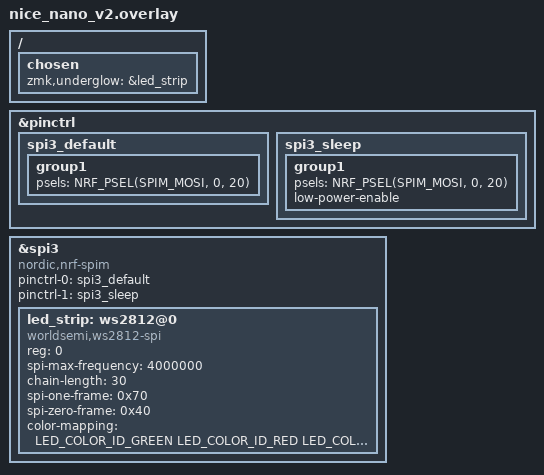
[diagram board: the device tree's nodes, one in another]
#include <dt-bindings/led/led.h>

/*
 * Official Keyball44 PCB (Yowkees) + QMK use WS2812_DI_PIN D3.
 * On nice!nano / ProMicro nRF52840 that is P0.20.
 * spi3 keeps the right-half trackball on spi1.
 *
 * Note: OLED I2C SCL is also on D3/P0.20 on this PCB. QMK bitbangs around
 * that; ZMK's SPI strip driver owns the pin. If OLED glitches after flashing,
 * that pin share is the reason — report back and we can tune.
 */
&pinctrl {
    spi3_default: spi3_default {
        group1 {
            psels = <NRF_PSEL(SPIM_MOSI, 0, 20)>;
        };
    };

    spi3_sleep: spi3_sleep {
        group1 {
            psels = <NRF_PSEL(SPIM_MOSI, 0, 20)>;
            low-power-enable;
        };
    };
};

&spi3 {
    compatible = "nordic,nrf-spim";
    status = "okay";

    pinctrl-0 = <&spi3_default>;
    pinctrl-1 = <&spi3_sleep>;
    pinctrl-names = "default", "sleep";

    led_strip: ws2812@0 {
        compatible = "worldsemi,ws2812-spi";
        reg = <0>;
        spi-max-frequency = <4000000>;

        /* Official Keyball44: RGBLED_SPLIT { 30, 30 } */
        chain-length = <30>;
        spi-one-frame = <0x70>;
        spi-zero-frame = <0x40>;

        color-mapping = <LED_COLOR_ID_GREEN
                         LED_COLOR_ID_RED
                         LED_COLOR_ID_BLUE>;
    };
};

/ {
    chosen {
        zmk,underglow = &led_strip;
    };
};
